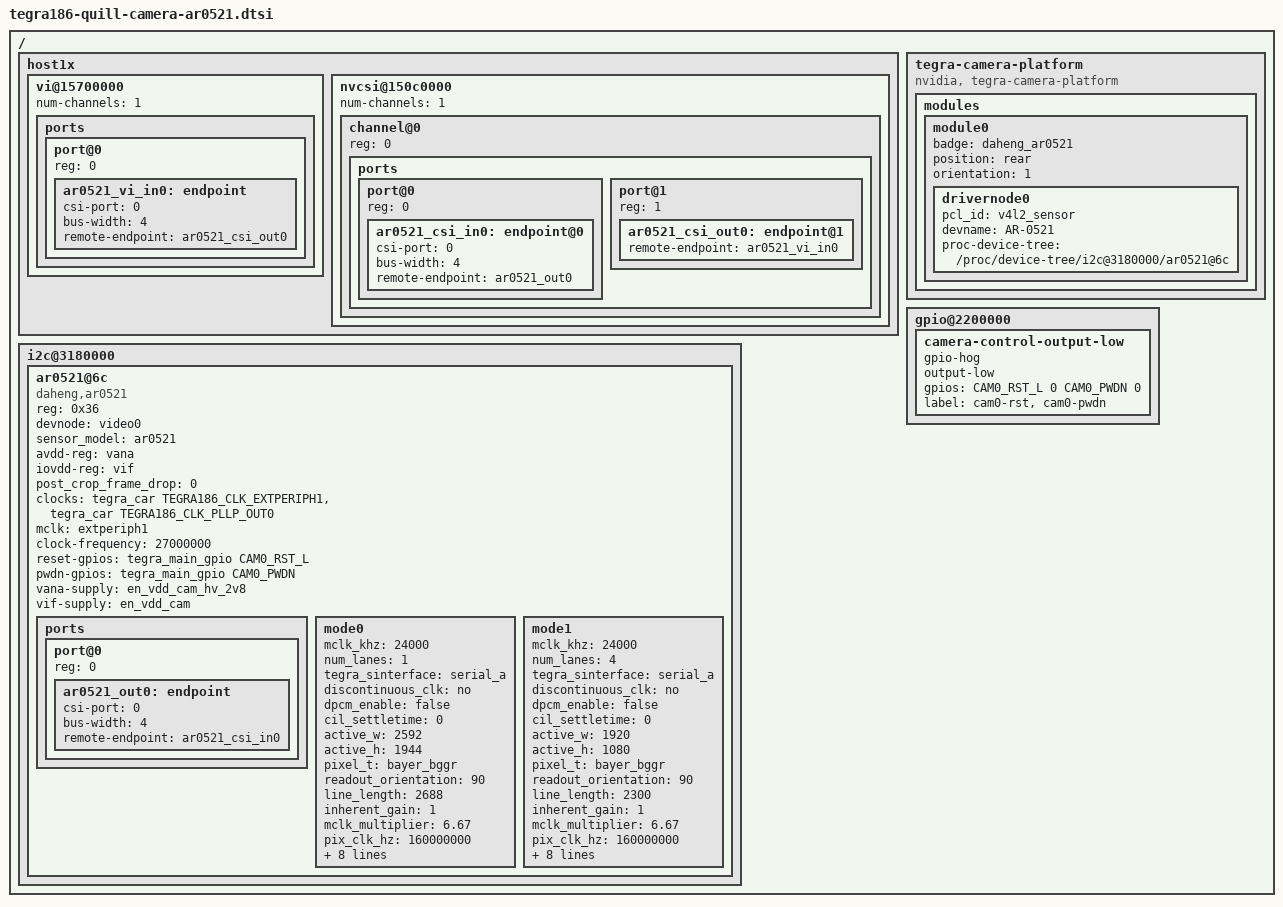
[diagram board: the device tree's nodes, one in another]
/* Econ device tree for ar0521 support */
#include <dt-bindings/media/camera.h>
#include <dt-bindings/platform/t210/t210.h>
#include "dt-bindings/clock/tegra186-clock.h"

/ {
	host1x {
		vi@15700000 {
			num-channels = <1>;
			ports {
				#address-cells = <1>;
				#size-cells = <0>;
				port@0 {
					reg = <0>;
					ar0521_vi_in0: endpoint {
						csi-port = <0>;
						bus-width = <4>;
						remote-endpoint = <&ar0521_csi_out0>;
					};
				};
			};
		};

		nvcsi@150c0000 {
			num-channels = <1>;
			#address-cells = <1>;
			#size-cells = <0>;
			channel@0 {
				reg = <0>;
				ports {
					#address-cells = <1>;
					#size-cells = <0>;
					port@0 {
						reg = <0>;
						ar0521_csi_in0: endpoint@0 {
							csi-port = <0>;
							bus-width = <4>;
							remote-endpoint = <&ar0521_out0>;
						};
					};
					port@1 {
						reg = <1>;
						ar0521_csi_out0: endpoint@1 {
							remote-endpoint = <&ar0521_vi_in0>;
						};
					};
				};
			};
		};

	};

	i2c@3180000 {
		status = "okay";
		#address-cells = <1>;
		#size-cells = <0>;
		ar0521@6c {
			status = "okay";
			compatible = "daheng,ar0521";
			reg = <0x36>;

			/* V4L2 device node location */
			devnode = "video0";

			sensor_model ="ar0521";
			avdd-reg = "vana";
			iovdd-reg = "vif";
			post_crop_frame_drop = "0";
			clocks = <&tegra_car TEGRA186_CLK_EXTPERIPH1>,
					 <&tegra_car TEGRA186_CLK_PLLP_OUT0>;
			clock-names = "extperiph1", "pllp_grtba";
			mclk = "extperiph1";
			clock-frequency = <27000000>;
			reset-gpios = <&tegra_main_gpio CAM0_RST_L GPIO_ACTIVE_HIGH>;
			pwdn-gpios = <&tegra_main_gpio CAM0_PWDN GPIO_ACTIVE_HIGH>; 
			vana-supply = <&en_vdd_cam_hv_2v8>;
			vif-supply = <&en_vdd_cam>;
			ports {
				#address-cells = <1>;
				#size-cells = <0>;
				port@0 {
					reg = <0>;
					ar0521_out0: endpoint {
						csi-port = <0>;
						bus-width = <4>;
						remote-endpoint = <&ar0521_csi_in0>;
					};
				};
			};

			/**
			* A modeX node is required to support v4l2 driver
			* implementation with NVIDIA camera software stack
			*
			* mclk_khz = "";
			* Standard MIPI driving clock, typically 24MHz
			*
			* num_lanes = "";
			* Number of lane channels sensor is programmed to output
			*
			* tegra_sinterface = "";
			* The base tegra serial interface lanes are connected to
			*
			* discontinuous_clk = "";
			* The sensor is programmed to use a discontinuous clock on MIPI lanes
			*
			* dpcm_enable = "true";
			* The sensor is programmed to use a DPCM modes
			*
			* cil_settletime = "";
			* MIPI lane settle time value.
			* A "0" value attempts to autocalibrate based on mclk_multiplier
			*
			*
			*
			*
			* active_w = "";
			* Pixel active region width
			*
			* active_h = "";
			* Pixel active region height
			*
			* pixel_t = "";
			* The sensor readout pixel pattern
			*
			* readout_orientation = "0";
			* Based on camera module orientation.
			* Only change readout_orientation if you specifically
			* Program a different readout order for this mode
			*
			* line_length = "";
			* Pixel line length (width) for sensor mode.
			* This is used to calibrate features in our camera stack.
			*
			* mclk_multiplier = "";
			* Multiplier to MCLK to help time hardware capture sequence
			* TODO: Assign to PLL_Multiplier as well until fixed in core
			*
			* pix_clk_hz = "";
			* Sensor pixel clock used for calculations like exposure and framerate
			*
			*
			*
			*
			* inherent_gain = "";
			* Gain obtained inherently from mode (ie. pixel binning)
			*
			* min_gain_val = ""; (floor to 6 decimal places)
			* max_gain_val = ""; (floor to 6 decimal places)
			* Gain limits for mode
			*
			* min_exp_time = ""; (ceil to integer)
			* max_exp_time = ""; (ceil to integer)
			* Exposure Time limits for mode (us)
			*
			*
			* min_hdr_ratio = "";
			* max_hdr_ratio = "";
			* HDR Ratio limits for mode
			*
			* min_framerate = "";
			* max_framerate = "";
			* Framerate limits for mode (fps)
			*/

			 mode0 { 	// MODE_2592X1944
						mclk_khz = "24000";
						num_lanes = "1";
						tegra_sinterface = "serial_a";
						discontinuous_clk = "no";
						dpcm_enable = "false";
						cil_settletime = "0";

						active_w = "2592";
						active_h = "1944";
						pixel_t = "bayer_bggr";
						readout_orientation = "90";
						line_length = "2688";
						inherent_gain = "1";
						mclk_multiplier = "6.67";
						pix_clk_hz = "160000000";

						min_gain_val = "1.0";
						max_gain_val = "16";
						min_hdr_ratio = "1";
						max_hdr_ratio = "64";
						min_framerate = "1.816577";
						max_framerate = "30";
						min_exp_time = "34";
						max_exp_time = "550385";
					};

			mode1 { // MODE_1920X1080
						mclk_khz = "24000";
						num_lanes = "4";
						tegra_sinterface = "serial_a";
						discontinuous_clk = "no";
						dpcm_enable = "false";
						cil_settletime = "0";

						active_w = "1920";
						active_h = "1080";
						pixel_t = "bayer_bggr";
						readout_orientation = "90";
						line_length = "2300";
						inherent_gain = "1";
						mclk_multiplier = "6.67";
						pix_clk_hz = "160000000";

						min_gain_val = "1.0";
						max_gain_val = "16";
						min_hdr_ratio = "1";
						max_hdr_ratio = "64";
						min_framerate = "1.816577";
						max_framerate = "100";
						min_exp_time = "34";
						max_exp_time = "550385";
					}; 
		};
	};

	tegra-camera-platform {
		compatible = "nvidia, tegra-camera-platform";
		modules {
			module0 {
				badge = "daheng_ar0521";
				position = "rear";
				orientation = "1";
				drivernode0 {
					pcl_id = "v4l2_sensor";
					devname = "AR-0521";
					proc-device-tree = "/proc/device-tree/i2c@3180000/ar0521@6c";
					status = "okay";
				};
			};
		};
	};

	gpio@2200000 {
		camera-control-output-low {
			gpio-hog;
			output-low;
			gpios = <CAM0_RST_L 0 CAM0_PWDN 0>;
			label = "cam0-rst", "cam0-pwdn";
		};
	};

};
